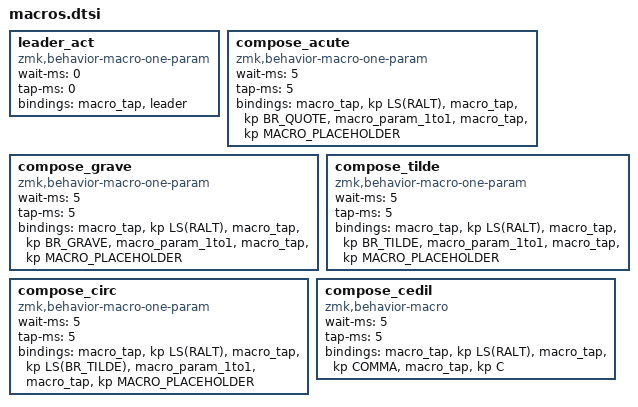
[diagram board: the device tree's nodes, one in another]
leader_act: leader_act {
  compatible = "zmk,behavior-macro-one-param";
  #binding-cells = <1>;
  wait-ms = <0>;
  tap-ms = <0>;
  bindings = <&macro_tap &leader>;
};
// compose key for accented chars: '=acute, `=grave, ~=tilde, ^=circ, ,+c=cedil
// OS: set compose key to Shift+Right Alt (Wayland: DE settings, X11: setxkbmap)
compose_acute: compose_acute {
  compatible = "zmk,behavior-macro-one-param";
  #binding-cells = <1>; wait-ms = <5>; tap-ms = <5>;
  bindings = <&macro_tap &kp LS(RALT)>, <&macro_tap &kp BR_QUOTE>,
    <&macro_param_1to1>, <&macro_tap &kp MACRO_PLACEHOLDER>;
};
compose_grave: compose_grave {
  compatible = "zmk,behavior-macro-one-param";
  #binding-cells = <1>; wait-ms = <5>; tap-ms = <5>;
  bindings = <&macro_tap &kp LS(RALT)>, <&macro_tap &kp BR_GRAVE>,
    <&macro_param_1to1>, <&macro_tap &kp MACRO_PLACEHOLDER>;
};
compose_tilde: compose_tilde {
  compatible = "zmk,behavior-macro-one-param";
  #binding-cells = <1>; wait-ms = <5>; tap-ms = <5>;
  bindings = <&macro_tap &kp LS(RALT)>, <&macro_tap &kp BR_TILDE>,
    <&macro_param_1to1>, <&macro_tap &kp MACRO_PLACEHOLDER>;
};
compose_circ: compose_circ {
  compatible = "zmk,behavior-macro-one-param";
  #binding-cells = <1>; wait-ms = <5>; tap-ms = <5>;
  bindings = <&macro_tap &kp LS(RALT)>, <&macro_tap &kp LS(BR_TILDE)>,
    <&macro_param_1to1>, <&macro_tap &kp MACRO_PLACEHOLDER>;
};
compose_cedil: compose_cedil {
  compatible = "zmk,behavior-macro";
  #binding-cells = <0>; wait-ms = <5>; tap-ms = <5>;
  bindings = <&macro_tap &kp LS(RALT)>, <&macro_tap &kp COMMA>, <&macro_tap &kp C>;
};
